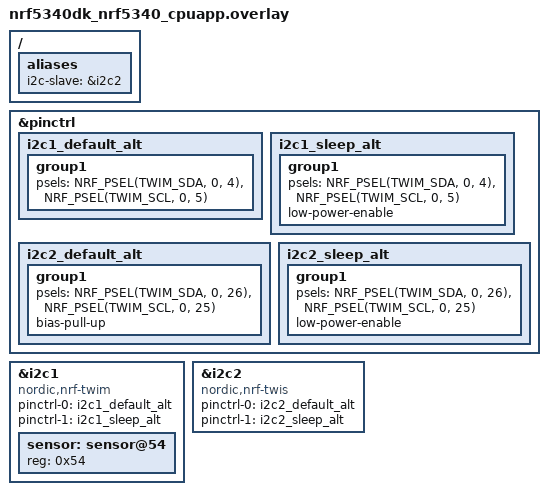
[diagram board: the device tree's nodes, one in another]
/ {
	aliases {
		i2c-slave = &i2c2;
	};
};

&pinctrl {
	i2c1_default_alt: i2c1_default_alt {
		group1 {
			psels = <NRF_PSEL(TWIM_SDA, 0, 4)>,
				<NRF_PSEL(TWIM_SCL, 0, 5)>;
		};
	};

	i2c1_sleep_alt: i2c1_sleep_alt {
		group1 {
			psels = <NRF_PSEL(TWIM_SDA, 0, 4)>,
				<NRF_PSEL(TWIM_SCL, 0, 5)>;
			low-power-enable;
		};
	};

	i2c2_default_alt: i2c2_default_alt {
		group1 {
/* Temporary workaround as it is currently not possible
 * to configure pins for TWIS with pinctrl. */
			psels = <NRF_PSEL(TWIM_SDA, 0, 26)>,
				<NRF_PSEL(TWIM_SCL, 0, 25)>;
			bias-pull-up;
		};
	};

	i2c2_sleep_alt: i2c2_sleep_alt {
		group1 {
			psels = <NRF_PSEL(TWIM_SDA, 0, 26)>,
				<NRF_PSEL(TWIM_SCL, 0, 25)>;
			low-power-enable;
		};
	};
};

&i2c1 {
	compatible = "nordic,nrf-twim";
	status = "okay";
	pinctrl-0 = <&i2c1_default_alt>;
	pinctrl-1 = <&i2c1_sleep_alt>;
	pinctrl-names = "default", "sleep";
	sensor: sensor@54 {
		reg = <0x54>;
	};
};

&i2c2 {
	compatible = "nordic,nrf-twis";
	pinctrl-0 = <&i2c2_default_alt>;
	pinctrl-1 = <&i2c2_sleep_alt>;
	pinctrl-names = "default", "sleep";
};
